# STM32H7B3xxQ register map
File version: 1.0
Registers are 32-bit, read-write, reset 0x0 unless marked. A register's access mark holds for its fields unless they carry their own. Offsets are from the block's base; [hi:lo] are bit positions.

## CRS — Clock Recovery System
Base 0x40008400
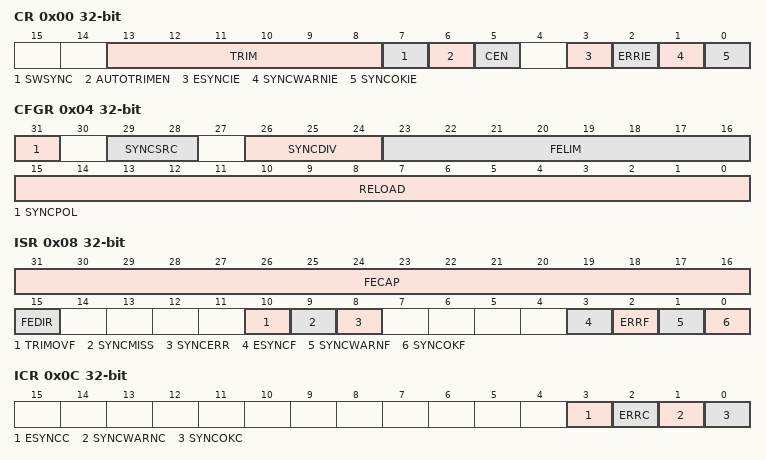
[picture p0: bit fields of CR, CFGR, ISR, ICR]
0x00 CR — CRS ccontrol register
  [13:8] TRIM — HSI48 oscillator smooth trimming
  [7] SWSYNC — Generate software SYNC event
  [6] AUTOTRIMEN — Automatic trimming enable
  [5] CEN — Frequency error counter enable
  [3] ESYNCIE — Expected SYNC interrupt enable
  [2] ERRIE — SYNC error or trimming error interrupt enable
  [1] SYNCWARNIE — SYNC warning interrupt enable
  [0] SYNCOKIE — SYNC event OK interrupt enable
0x04 CFGR — CRS configuration register
  [31] SYNCPOL — SYNC polarity selection
    0=RISING (Synchro Active on rising edge (default)); 1=FALLING (Synchro Active on falling edge)
  [29:28] SYNCSRC — SYNC signal source selection
    0=GPIO (Synchro Signal source GPIO); 1=LSE (Synchro Signal source LSE); 2=USB (Synchro Signal source USB SOF (default))
  [26:24] SYNCDIV — SYNC divider
    0=DIV_1 (Synchro Signal not divided (default)); 1=DIV_2 (Synchro Signal divided by 2); 2=DIV_4 (Synchro Signal divided by 4); 3=DIV_8 (Synchro Signal divided by 8); 4=DIV_16 (Synchro Signal divided by 16); 5=DIV_32 (Synchro Signal divided by 32); 6=DIV_64 (Synchro Signal divided by 64); 7=DIV_128 (Synchro Signal divided by 128)
  [23:16] FELIM — Frequency error limit
  [15:0] RELOAD — Counter reload value
0x08 ISR — CRS interrupt and status register
  [31:16] FECAP — Frequency error capture
  [15] FEDIR — Frequency error direction
    0=UP (Upcounting direction, the actual frequency is above the target); 1=DOWN (Downcounting direction, the actual frequency is below the target)
  [10] TRIMOVF — Trimming overflow or underflow
  [9] SYNCMISS — SYNC missed
  [8] SYNCERR — SYNC error
  [3] ESYNCF — Expected SYNC flag
  [2] ERRF — Error flag
  [1] SYNCWARNF — SYNC warning flag
  [0] SYNCOKF — SYNC event OK flag
0x0C ICR — CRS interrupt flag clear register
  [3] ESYNCC — Expected SYNC clear flag
  [2] ERRC — Error clear flag
  [1] SYNCWARNC — SYNC warning clear flag
  [0] SYNCOKC — SYNC event OK clear flag

## SWPMI1 — Single Wire Protocol Master Interface SPWMI
Base 0x40008800
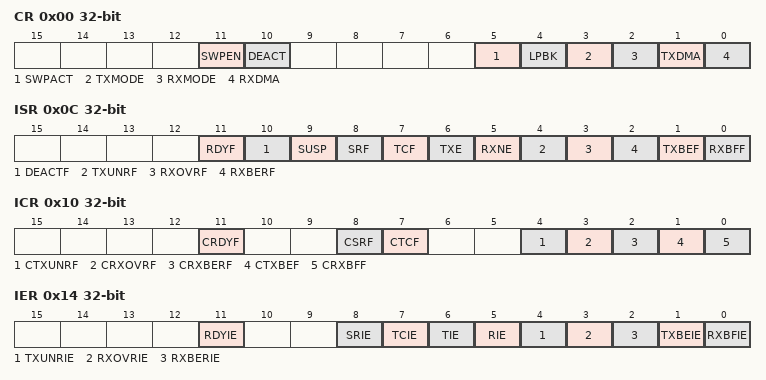
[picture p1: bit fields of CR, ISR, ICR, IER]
0x00 CR — SWPMI Configuration/Control register
  [11] SWPEN — Single wire protocol master transceiver enable
  [10] DEACT — Single wire protocol master interface deactivate
  [5] SWPACT — Single wire protocol master interface activate
  [4] LPBK — Loopback mode enable
  [3] TXMODE — Transmission buffering mode
    0=SINGLE (Single software buffer mode for transmission); 1=MULTI (Multi software buffermode for transmission)
  [2] RXMODE — Reception buffering mode
    0=SINGLE (Single software buffer mode for reception); 1=MULTI (Multi software buffermode for reception)
  [1] TXDMA — Transmission DMA enable
  [0] RXDMA — Reception DMA enable
0x04 BRR — SWPMI bitrate register
  [7:0] BR — BR[7:0] bits (Bitrate prescaler)
0x0C ISR — SWPMI Interrupt and Status register
  [11] RDYF — Transceiver ready flag
  [10] DEACTF — DEACTIVATED flag
  [9] SUSP — SUSPEND flag
  [8] SRF — Slave resume flag
  [7] TCF — Transfer complete flag
  [6] TXE — Transmit data register empty
  [5] RXNE — Receive data register not empty
  [4] TXUNRF — Transmit underrun error flag
  [3] RXOVRF — Receive overrun error flag
  [2] RXBERF — Receive CRC error flag
  [1] TXBEF — Transmit buffer empty flag
  [0] RXBFF — Receive buffer full flag
0x10 ICR — SWPMI Interrupt Flag Clear register
  [11] CRDYF — Clear transceiver ready flag
  [8] CSRF — Clear slave resume flag
  [7] CTCF — Clear transfer complete flag
  [4] CTXUNRF — Clear transmit underrun error flag
  [3] CRXOVRF — Clear receive overrun error flag
  [2] CRXBERF — Clear receive CRC error flag
  [1] CTXBEF — Clear transmit buffer empty flag
  [0] CRXBFF — Clear receive buffer full flag
0x14 IER — SWPMI Interrupt Enable register
  [11] RDYIE — Transceiver ready interrupt enable
  [8] SRIE — Slave resume interrupt enable
  [7] TCIE — Transmit complete interrupt enable
  [6] TIE — Transmit interrupt enable
  [5] RIE — Receive interrupt enable
  [4] TXUNRIE — Transmit underrun error interrupt enable
  [3] RXOVRIE — Receive overrun error interrupt enable
  [2] RXBERIE — Receive CRC error interrupt enable
  [1] TXBEIE — Transmit buffer empty interrupt enable
  [0] RXBFIE — Receive buffer full interrupt enable
0x18 RFL — SWPMI Receive Frame Length register
  [4:0] RFL — RFL[4:0] bits (Receive Frame length)
0x1C TDR — SWPMI Transmit data register
  [31:0] TD — Transmit Data Register
0x20 RDR — SWPMI Receive data register
  [31:0] RD — Receive Data Register
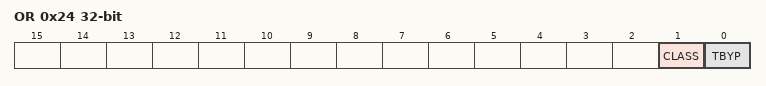
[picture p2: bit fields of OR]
0x24 OR — SWPMI Option register
  [1] CLASS — SWP CLASS selection
    0=C (SWPMI_IO uses directly VDD voltage to operate in class C); 1=B (SWPMI_IO uses an internal voltage regulator to operate in class B)
  [0] TBYP — SWP Transceiver Bypass
